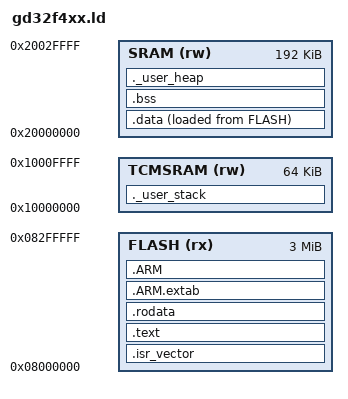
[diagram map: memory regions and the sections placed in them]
MEMORY
{
  FLASH (rx)            : ORIGIN = 0x08000000, LENGTH = 3072K
  TCMSRAM (rw)          : ORIGIN = 0x10000000, LENGTH = 64K
  SRAM (rw)             : ORIGIN = 0x20000000, LENGTH = 192K
}

/* Entry Point */
ENTRY(Reset_Handler)

/* Highest address of the user mode stack */
_estack = ORIGIN(SRAM) + LENGTH(SRAM);    /* end of RAM */
/* Generate a link error if heap and stack don't fit into RAM */
_Min_Heap_Size = 0x400 ;      /* required amount of heap  */
_Min_Stack_Size = 0x400 ; /* required amount of stack */

/* Define output sections */
SECTIONS
{
  /* The startup code goes first into FLASH */
  .isr_vector :
  {
    . = ALIGN(4);
    KEEP(*(.isr_vector)) /* Startup code */
    . = ALIGN(4);
  } >FLASH

  /* The program code and other data goes into FLASH */
  .text :
  {
    . = ALIGN(4);
    _stext = .;
    *(.text)           /* .text sections (code) */
    *(.text*)          /* .text* sections (code) */
    *(.glue_7)         /* glue arm to thumb code */
    *(.glue_7t)        /* glue thumb to arm code */
    *(.eh_frame)

    . = ALIGN(4);
    __usbh_class_info_start__ = .;
    KEEP(*(.usbh_class_info))
    __usbh_class_info_end__ = .;

    . = ALIGN(4);
    _etext = .;        /* define a global symbols at end of code */
  } >FLASH

  /* Constant data goes into FLASH */
  .rodata :
  {
    . = ALIGN(4);
    *(.rodata)         /* .rodata sections (constants, strings, etc.) */
    *(.rodata*)        /* .rodata* sections (constants, strings, etc.) */
    . = ALIGN(4);
  } >FLASH

  .ARM.extab   : { *(.ARM.extab* .gnu.linkonce.armextab.*) } >FLASH
  .ARM : {
    __exidx_start = .;
    *(.ARM.exidx*)
    __exidx_end = .;
  } >FLASH


  /* used by the startup to initialize data */
  _sidata = LOADADDR(.data);

  /* Initialized data sections goes into RAM, load LMA copy after code */
  .data :
  {
    . = ALIGN(4);
    _sdata = .;        /* create a global symbol at data start */
    *(.data)           /* .data sections */
    *(.data*)          /* .data* sections */
    *(.RamFunc)        /* .RamFunc sections */
    *(.RamFunc*)       /* .RamFunc* sections */

    . = ALIGN(4);
    _edata = .;        /* define a global symbol at data end */
  } >SRAM AT> FLASH


  /* Uninitialized data section */
  . = ALIGN(4);
  .bss :
  {
    /* This is used by the startup in order to initialize the .bss section */
    _sbss = .;         /* define a global symbol at bss start */
    __bss_start = _sbss;
    *(.bss)
    *(.bss*)
    *(COMMON)

    . = ALIGN(4);
    _ebss = .;         /* define a global symbol at bss end */
    __bss_end = _ebss;
  } >SRAM

  ._user_heap :
  {
    . = ALIGN(8);
    _sheap = .;
    . = . + _Min_Heap_Size;
    . = ALIGN(8);
    PROVIDE ( end = . );
    PROVIDE ( _end = . );    
    _eheap = .;
  } >SRAM

  ._user_stack :
  {
    . = ALIGN(8);
    _sstack = .;
    . = .+ _Min_Stack_Size;
    . = ALIGN(8);
    _estack = .;
  } >TCMSRAM

  /* Remove information from the standard libraries */
  /DISCARD/ :
  {
    libc.a ( * )
    libm.a ( * )
    libgcc.a ( * )
  }

  .ARM.attributes 0 : { *(.ARM.attributes) }
}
